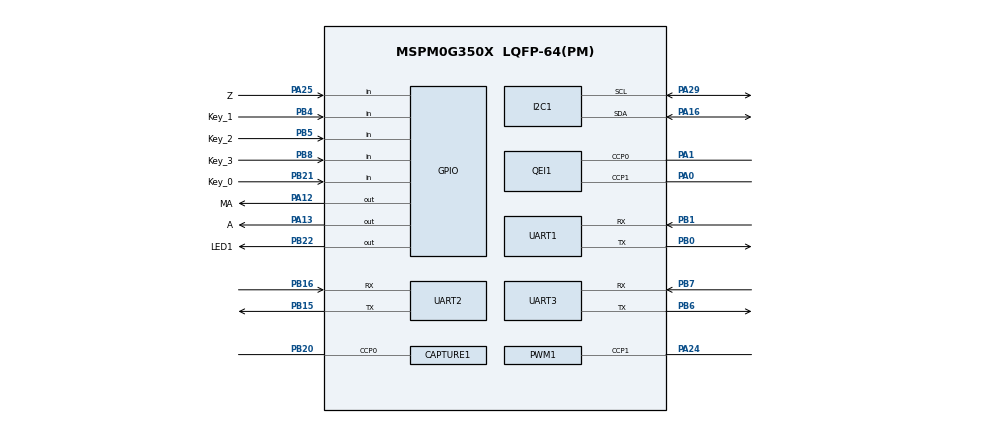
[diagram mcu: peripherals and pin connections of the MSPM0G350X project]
/**
 * @cliArgs --device "MSPM0G350X" --part "Default" --package "LQFP-64(PM)" --product "mspm0_sdk@2.11.00.07"
 * @versions {"tool":"1.26.2+4477"}
 */

/* Only peripherals used by the cleaned balance-board project are retained. */
const CAPTURE       = scripting.addModule("/ti/driverlib/CAPTURE", {}, false);
const CAPTURE1      = CAPTURE.addInstance();
const GPIO          = scripting.addModule("/ti/driverlib/GPIO", {}, false);
const GPIO1         = GPIO.addInstance();
const GPIO2         = GPIO.addInstance();
const GPIO3         = GPIO.addInstance();
const GPIO4         = GPIO.addInstance();
const GPIO5         = GPIO.addInstance();
const I2C           = scripting.addModule("/ti/driverlib/I2C", {}, false);
const I2C1          = I2C.addInstance();
const PWM           = scripting.addModule("/ti/driverlib/PWM", {}, false);
const PWM1          = PWM.addInstance();
const QEI           = scripting.addModule("/ti/driverlib/QEI", {}, false);
const QEI1          = QEI.addInstance();
const SYSCTL        = scripting.addModule("/ti/driverlib/SYSCTL");
const SYSTICK       = scripting.addModule("/ti/driverlib/SYSTICK");
const TIMER         = scripting.addModule("/ti/driverlib/TIMER", {}, false);
const TIMER1        = TIMER.addInstance();
const UART          = scripting.addModule("/ti/driverlib/UART", {}, false);
const UART1         = UART.addInstance();
const UART2         = UART.addInstance();
const UART3         = UART.addInstance();
const ProjectConfig = scripting.addModule("/ti/project_config/ProjectConfig");
const Board         = scripting.addModule("/ti/driverlib/Board", {}, false);

const divider9       = system.clockTree["UDIV"];
divider9.divideValue = 2;

const gate8  = system.clockTree["MFPCLKGATE"];
gate8.enable = true;

const multiplier2         = system.clockTree["PLL_QDIV"];
multiplier2.multiplyValue = 4;

const mux4       = system.clockTree["EXHFMUX"];
mux4.inputSelect = "EXHFMUX_XTAL";

const mux8       = system.clockTree["HSCLKMUX"];
mux8.inputSelect = "HSCLKMUX_SYSPLL0";

const mux12       = system.clockTree["SYSPLLMUX"];
mux12.inputSelect = "zSYSPLLMUX_HFCLK";

const pinFunction4       = system.clockTree["HFXT"];
pinFunction4.inputFreq   = 40;
pinFunction4.enable      = true;
pinFunction4.HFXTStartup = 10;

CAPTURE1.$name                              = "ENCODER_PWM";
CAPTURE1.timerStartTimer                    = true;
CAPTURE1.timerPeriod                        = "50 ms";
CAPTURE1.captMode                           = "COMBINED";
CAPTURE1.interrupts                         = ["CC0_DN","CC1_DN"];
CAPTURE1.peripheral.$assign                 = "TIMG12";
CAPTURE1.peripheral.ccp0Pin.$assign         = "PB20";
CAPTURE1.ccp0PinConfig.$name                = "ti_driverlib_gpio_GPIOPinGeneric1";
CAPTURE1.ccp0PinConfig.hideOutputInversion  = scripting.forceWrite(false);
CAPTURE1.ccp0PinConfig.onlyInternalResistor = scripting.forceWrite(false);
CAPTURE1.ccp0PinConfig.passedPeripheralType = scripting.forceWrite("Digital");

GPIO1.$name                         = "LEDs";
GPIO1.associatedPins[0].$name       = "LED1";
GPIO1.associatedPins[0].pin.$assign = "PB22";

GPIO2.$name                              = "Keys";
GPIO2.associatedPins.create(4);
GPIO2.associatedPins[0].direction        = "INPUT";
GPIO2.associatedPins[0].internalResistor = "PULL_UP";
GPIO2.associatedPins[0].$name            = "Key_0";
GPIO2.associatedPins[0].pin.$assign      = "PB21";
GPIO2.associatedPins[1].direction        = "INPUT";
GPIO2.associatedPins[1].internalResistor = "PULL_UP";
GPIO2.associatedPins[1].$name            = "Key_1";
GPIO2.associatedPins[1].pin.$assign      = "PB4";
GPIO2.associatedPins[2].direction        = "INPUT";
GPIO2.associatedPins[2].internalResistor = "PULL_UP";
GPIO2.associatedPins[2].$name            = "Key_2";
GPIO2.associatedPins[2].pin.$assign      = "PB5";
GPIO2.associatedPins[3].direction        = "INPUT";
GPIO2.associatedPins[3].internalResistor = "PULL_UP";
GPIO2.associatedPins[3].$name            = "Key_3";
GPIO2.associatedPins[3].pin.$assign      = "PB8";

GPIO3.$name                         = "DIR";
GPIO3.associatedPins[0].$name       = "A";
GPIO3.associatedPins[0].pin.$assign = "PA13";

GPIO4.$name                         = "EN";
GPIO4.associatedPins[0].$name       = "MA";
GPIO4.associatedPins[0].pin.$assign = "PA12";

GPIO5.$name                              = "ENCODER_Z";
GPIO5.associatedPins[0].$name            = "Z";
GPIO5.associatedPins[0].direction        = "INPUT";
GPIO5.associatedPins[0].internalResistor = "PULL_DOWN";
GPIO5.associatedPins[0].interruptEn      = true;
GPIO5.associatedPins[0].polarity         = "RISE";
GPIO5.associatedPins[0].pin.$assign      = "PA25";

/* MPU6050 hardware I2C: PA16 SDA, PA29 SCL. */
I2C1.$name                             = "I2C_MPU";
I2C1.basicEnableController             = true;
I2C1.basicControllerStandardBusSpeed   = "Fast";
I2C1.peripheral.$assign                = "I2C1";
I2C1.peripheral.sdaPin.$assign         = "PA16";
I2C1.peripheral.sclPin.$assign         = "PA29";
I2C1.sdaPinConfig.hideOutputInversion  = scripting.forceWrite(false);
I2C1.sdaPinConfig.onlyInternalResistor = scripting.forceWrite(false);
I2C1.sdaPinConfig.passedPeripheralType = scripting.forceWrite("Digital");
I2C1.sdaPinConfig.$name                = "ti_driverlib_gpio_GPIOPinGeneric14";
I2C1.sclPinConfig.hideOutputInversion  = scripting.forceWrite(false);
I2C1.sclPinConfig.onlyInternalResistor = scripting.forceWrite(false);
I2C1.sclPinConfig.passedPeripheralType = scripting.forceWrite("Digital");
I2C1.sclPinConfig.$name                = "ti_driverlib_gpio_GPIOPinGeneric15";

PWM1.$name                      = "PWM_0";
PWM1.clockPrescale              = 80;
PWM1.ccIndex                    = [1];
PWM1.ccp1PinConfig.$name        = "ti_driverlib_gpio_GPIOPinGeneric2";
PWM1.peripheral.$assign         = "TIMA1";
PWM1.peripheral.ccp1Pin.$assign = "PA24";
PWM1.PWM_CHANNEL_1.$name        = "ti_driverlib_pwm_PWMTimerCC0";

QEI1.$name                      = "QEI_0";
QEI1.timerStartTimer            = true;
QEI1.peripheral.$assign         = "TIMG8";
QEI1.peripheral.ccp0Pin.$assign = "PA1";
QEI1.peripheral.ccp1Pin.$assign = "PA0";
QEI1.ccp0PinConfig.$name        = "ti_driverlib_gpio_GPIOPinGeneric4";
QEI1.ccp1PinConfig.$name        = "ti_driverlib_gpio_GPIOPinGeneric7";

/* 5 ms encoder/stepper scheduler. */
TIMER1.$name              = "TIMER_0";
TIMER1.timerMode          = "PERIODIC";
TIMER1.interrupts         = ["ZERO"];
TIMER1.timerClkPrescale   = 200;
TIMER1.timerPeriod        = "5ms";
TIMER1.timerStartTimer    = true;
TIMER1.peripheral.$assign = "TIMG0";

/* VOFA+/USB-UART. Restore the original balance-board UART0 pins. */
UART1.$name                    = "UART_0";
UART1.targetBaudRate           = 115200;
UART1.enabledInterrupts        = ["RX"];
UART1.peripheral.$assign       = "UART0";
UART1.peripheral.rxPin.$assign = "PB1";
UART1.peripheral.txPin.$assign = "PB0";
UART1.txPinConfig.$name        = "ti_driverlib_gpio_GPIOPinGeneric10";
UART1.rxPinConfig.$name        = "ti_driverlib_gpio_GPIOPinGeneric11";

/* MaixCAM2 link: legacy AA 55 12-byte frame, 115200 baud. */
UART2.$name                    = "UART_2";
UART2.targetBaudRate           = 115200;
UART2.enabledInterrupts        = ["RX"];
UART2.peripheral.$assign       = "UART2";
UART2.peripheral.rxPin.$assign = "PB16";
UART2.peripheral.txPin.$assign = "PB15";
UART2.txPinConfig.$name        = "ti_driverlib_gpio_GPIOPinGeneric3";
UART2.rxPinConfig.$name        = "ti_driverlib_gpio_GPIOPinGeneric9";

/* Full-duplex task handshake: car PB6(TX)->PB7(RX), balance PB6(TX)->car PB7(RX), 115200 8N1. */
UART3.$name                    = "UART_1";
UART3.targetBaudRate           = 115200;
UART3.enabledInterrupts        = ["RX"];
UART3.peripheral.$assign       = "UART1";
UART3.peripheral.rxPin.$assign = "PB7";
UART3.peripheral.txPin.$assign = "PB6";
UART3.txPinConfig.$name        = "ti_driverlib_gpio_GPIOPinGeneric16";
UART3.rxPinConfig.$name        = "ti_driverlib_gpio_GPIOPinGeneric17";

SYSCTL.forceDefaultClkConfig = true;
SYSCTL.clockTreeEn           = true;
SYSCTL.MFPCLKEn              = true;

ProjectConfig.genLibCMSIS = true;

pinFunction4.peripheral.$suggestSolution           = "SYSCTL";
pinFunction4.peripheral.hfxInPin.$suggestSolution  = "PA5";
pinFunction4.peripheral.hfxOutPin.$suggestSolution = "PA6";
Board.peripheral.$suggestSolution                  = "DEBUGSS";
Board.peripheral.swclkPin.$suggestSolution         = "PA20";
Board.peripheral.swdioPin.$suggestSolution         = "PA19";
